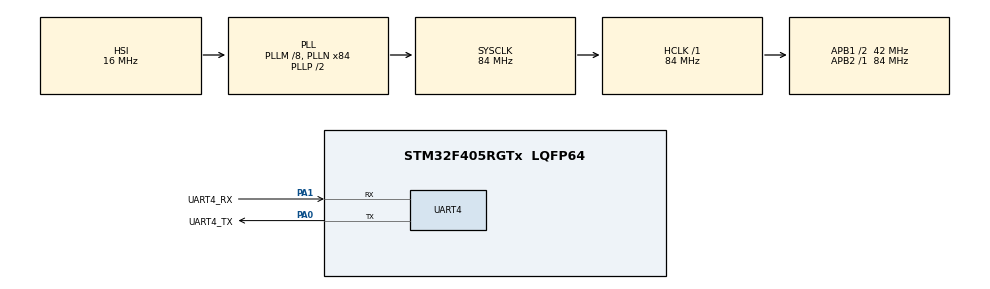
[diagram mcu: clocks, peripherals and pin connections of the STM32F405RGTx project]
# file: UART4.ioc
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Mcu.Family=STM32F4
Mcu.Name=STM32F405RGTx
Mcu.Package=LQFP64
NVIC.PriorityGroup=NVIC_PRIORITYGROUP_4
PA0-WKUP.GPIO_Label=UART4_TX
PA0-WKUP.Mode=Asynchronous
PA0-WKUP.Signal=UART4_TX
PA1.GPIO_Label=UART4_RX
PA1.Mode=Asynchronous
PA1.Signal=UART4_RX
PC14-OSC32_IN.Mode=LSE-External-Oscillator
PC14-OSC32_IN.Signal=RCC_OSC32_IN
PC15-OSC32_OUT.Mode=LSE-External-Oscillator
PC15-OSC32_OUT.Signal=RCC_OSC32_OUT
PH0-OSC_IN.Mode=HSE-External-Oscillator
PH0-OSC_IN.Signal=RCC_OSC_IN
PH1-OSC_OUT.Mode=HSE-External-Oscillator
PH1-OSC_OUT.Signal=RCC_OSC_OUT
ProjectManager.HeapSize=0x200
ProjectManager.StackSize=0x400
ProjectManager.TargetToolchain=MDK-ARM V5
RCC.48MHZClocksFreq_Value=42000000
RCC.AHBFreq_Value=84000000
RCC.APB1CLKDivider=RCC_HCLK_DIV2
RCC.APB1Freq_Value=42000000
RCC.APB1TimFreq_Value=84000000
RCC.APB2Freq_Value=84000000
RCC.APB2TimFreq_Value=84000000
RCC.CortexFreq_Value=84000000
RCC.HCLKFreq_Value=84000000
RCC.HSE_VALUE=8000000
RCC.HSI_VALUE=16000000
RCC.PLLM=8
RCC.PLLN=84
RCC.SYSCLKFreq_VALUE=84000000
RCC.SYSCLKSource=RCC_SYSCLKSOURCE_PLLCLK
RCC.VCOOutputFreq_Value=168000000
UART4.VirtualMode=Asynchronous
board=custom

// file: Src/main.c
/**
  ******************************************************************************
  * @file           : main.c
  * @brief          : Main program body
  ******************************************************************************
  ** This notice applies to any and all portions of this file
  * that are not between comment pairs USER CODE BEGIN and
  * USER CODE END. Other portions of this file, whether
  * inserted by the user or by software development tools
  * are owned by their respective copyright owners.
  *
  * COPYRIGHT(c) 2018 STMicroelectronics
  *
  * Redistribution and use in source and binary forms, with or without modification,
  * are permitted provided that the following conditions are met:
  *   1. Redistributions of source code must retain the above copyright notice,
  *      this list of conditions and the following disclaimer.
  *   2. Redistributions in binary form must reproduce the above copyright notice,
  *      this list of conditions and the following disclaimer in the documentation
  *      and/or other materials provided with the distribution.
  *   3. Neither the name of STMicroelectronics nor the names of its contributors
  *      may be used to endorse or promote products derived from this software
  *      without specific prior written permission.
  *
  * THIS SOFTWARE IS PROVIDED BY THE COPYRIGHT HOLDERS AND CONTRIBUTORS "AS IS"
  * AND ANY EXPRESS OR IMPLIED WARRANTIES, INCLUDING, BUT NOT LIMITED TO, THE
  * IMPLIED WARRANTIES OF MERCHANTABILITY AND FITNESS FOR A PARTICULAR PURPOSE ARE
  * DISCLAIMED. IN NO EVENT SHALL THE COPYRIGHT HOLDER OR CONTRIBUTORS BE LIABLE
  * FOR ANY DIRECT, INDIRECT, INCIDENTAL, SPECIAL, EXEMPLARY, OR CONSEQUENTIAL
  * DAMAGES (INCLUDING, BUT NOT LIMITED TO, PROCUREMENT OF SUBSTITUTE GOODS OR
  * SERVICES; LOSS OF USE, DATA, OR PROFITS; OR BUSINESS INTERRUPTION) HOWEVER
  * CAUSED AND ON ANY THEORY OF LIABILITY, WHETHER IN CONTRACT, STRICT LIABILITY,
  * OR TORT (INCLUDING NEGLIGENCE OR OTHERWISE) ARISING IN ANY WAY OUT OF THE USE
  * OF THIS SOFTWARE, EVEN IF ADVISED OF THE POSSIBILITY OF SUCH DAMAGE.
  *
  ******************************************************************************
  */
#include "main.h"
#include "stm32f4xx_hal.h"
#include "stdio.h"

#define PUTCHAR_PROTOTYPE int fputc(int ch, FILE *f)

UART_HandleTypeDef huart4;

/* USER CODE BEGIN PV */
/* Private variables ---------------------------------------------------------*/

/* USER CODE END PV */

void SystemClock_Config(void);
static void MX_GPIO_Init(void);
static void MX_UART4_Init(void);

/* USER CODE BEGIN PFP */
/* Private function prototypes -----------------------------------------------*/

/* USER CODE END PFP */

int main(void)
{
  /* USER CODE BEGIN 1 */
    int data;
    data = 0x02;
  /* USER CODE END 1 */

  /* MCU Configuration----------------------------------------------------------*/

  /* Reset of all peripherals, Initializes the Flash interface and the Systick. */
  HAL_Init();

  /* Configure the system clock */
  SystemClock_Config();

  /* Initialize all configured peripherals */
  MX_GPIO_Init();
  MX_UART4_Init();

  /* Infinite loop */
  /* USER CODE BEGIN WHILE */
  while (1)
  {
    ///HAL_UART_Transmit(&huart4, (uint8_t *)&data, 1, 0xFFFF);
    printf("1111111111111111111  uart4 \n");
  /* USER CODE END WHILE */

  }

}

void SystemClock_Config(void)
{

  RCC_OscInitTypeDef RCC_OscInitStruct;
  RCC_ClkInitTypeDef RCC_ClkInitStruct;

    /**Configure the main internal regulator output voltage
    */
  __HAL_RCC_PWR_CLK_ENABLE();

  __HAL_PWR_VOLTAGESCALING_CONFIG(PWR_REGULATOR_VOLTAGE_SCALE1);

    /**Initializes the CPU, AHB and APB busses clocks
    */
  RCC_OscInitStruct.OscillatorType = RCC_OSCILLATORTYPE_HSI;
  RCC_OscInitStruct.HSIState = RCC_HSI_ON;
  RCC_OscInitStruct.HSICalibrationValue = 16;
  RCC_OscInitStruct.PLL.PLLState = RCC_PLL_ON;
  RCC_OscInitStruct.PLL.PLLSource = RCC_PLLSOURCE_HSI;
  RCC_OscInitStruct.PLL.PLLM = 8;
  RCC_OscInitStruct.PLL.PLLN = 84;
  RCC_OscInitStruct.PLL.PLLP = RCC_PLLP_DIV2;
  RCC_OscInitStruct.PLL.PLLQ = 4;
  if (HAL_RCC_OscConfig(&RCC_OscInitStruct) != HAL_OK)
  {
    _Error_Handler(__FILE__, __LINE__);
  }

    /**Initializes the CPU, AHB and APB busses clocks
    */
  RCC_ClkInitStruct.ClockType = RCC_CLOCKTYPE_HCLK|RCC_CLOCKTYPE_SYSCLK
                              |RCC_CLOCKTYPE_PCLK1|RCC_CLOCKTYPE_PCLK2;
  RCC_ClkInitStruct.SYSCLKSource = RCC_SYSCLKSOURCE_PLLCLK;
  RCC_ClkInitStruct.AHBCLKDivider = RCC_SYSCLK_DIV1;
  RCC_ClkInitStruct.APB1CLKDivider = RCC_HCLK_DIV2;
  RCC_ClkInitStruct.APB2CLKDivider = RCC_HCLK_DIV1;

  if (HAL_RCC_ClockConfig(&RCC_ClkInitStruct, FLASH_LATENCY_2) != HAL_OK)
  {
    _Error_Handler(__FILE__, __LINE__);
  }

    /**Configure the Systick interrupt time
    */
  HAL_SYSTICK_Config(HAL_RCC_GetHCLKFreq()/1000);

    /**Configure the Systick
    */
  HAL_SYSTICK_CLKSourceConfig(SYSTICK_CLKSOURCE_HCLK);

  /* SysTick_IRQn interrupt configuration */
  HAL_NVIC_SetPriority(SysTick_IRQn, 0, 0);
}

/* UART4 init function */
static void MX_UART4_Init(void)
{

  huart4.Instance = UART4;
  huart4.Init.BaudRate = 115200;
  huart4.Init.WordLength = UART_WORDLENGTH_8B;
  huart4.Init.StopBits = UART_STOPBITS_1;
  huart4.Init.Parity = UART_PARITY_NONE;
  huart4.Init.Mode = UART_MODE_TX_RX;
  huart4.Init.HwFlowCtl = UART_HWCONTROL_NONE;
  huart4.Init.OverSampling = UART_OVERSAMPLING_16;
  if (HAL_UART_Init(&huart4) != HAL_OK)
  {
    _Error_Handler(__FILE__, __LINE__);
  }

}

/** Configure pins as
        * Analog
        * Input
        * Output
        * EVENT_OUT
        * EXTI
*/
static void MX_GPIO_Init(void)
{

  /* GPIO Ports Clock Enable */
  __HAL_RCC_GPIOC_CLK_ENABLE();
  __HAL_RCC_GPIOH_CLK_ENABLE();
  __HAL_RCC_GPIOA_CLK_ENABLE();

}

PUTCHAR_PROTOTYPE
{
  /* Place your implementation of fputc here */
  /* e.g. write a character to the EVAL_COM1 and Loop until the end of transmission */
  HAL_UART_Transmit(&huart4, (uint8_t *)&ch, 1, 0xFFFF);

  return ch;
}

void _Error_Handler(char *file, int line)
{
  while(1)
  {
  }
}

/************************ (C) COPYRIGHT STMicroelectronics *****END OF FILE****/
